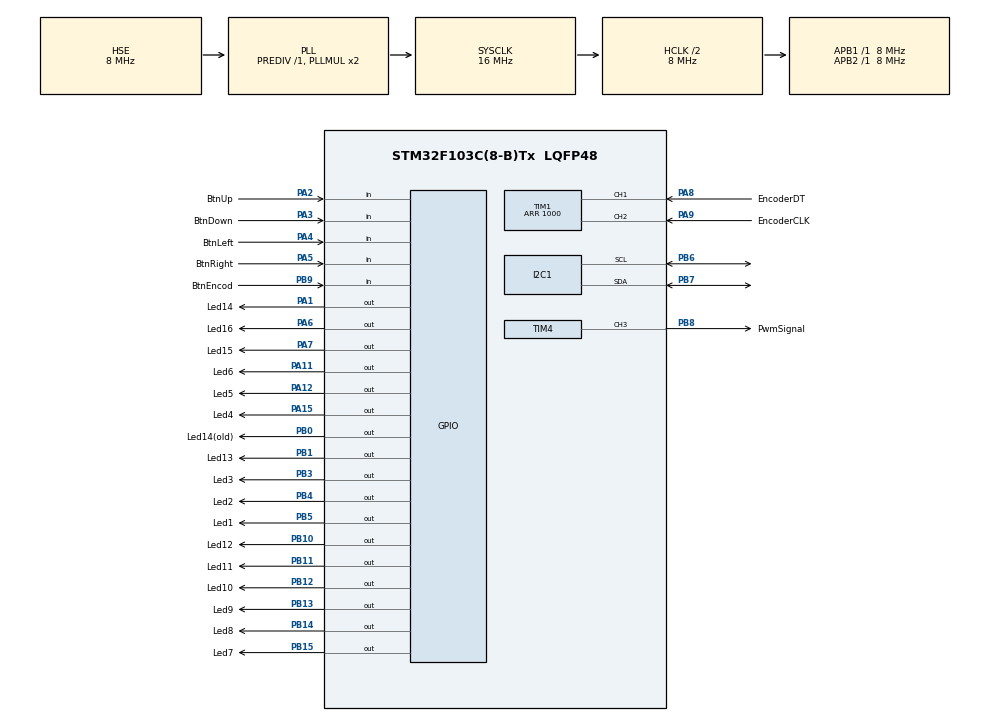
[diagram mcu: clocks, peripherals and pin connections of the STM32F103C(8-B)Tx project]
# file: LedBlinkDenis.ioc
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FREERTOS.BinarySemaphores01=SemBtnUp,Dynamic,NULL;SemBtnDown,Dynamic,NULL;SemBtnLeft,Dynamic,NULL;SemBtnRight,Dynamic,NULL;SemLcdLine1,Dynamic,NULL;SemLcdLine2,Dynamic,NULL;SemLcdLine3,Dynamic,NULL;SemLcdLine4,Dynamic,NULL;SemLcdRedrawMenu,Dynamic,NULL;SemLcdExitMenu,Dynamic,NULL;SemEncoderUp,Dynamic,NULL;SemEncoderDown,Dynamic,NULL;SemEncodBusy,Dynamic,NULL;SemLedMode1,Dynamic,NULL;SemLedMode2,Dynamic,NULL;SemLedMode3,Dynamic,NULL;SemLedMode4,Dynamic,NULL;SemLedMode5,Dynamic,NULL;SemLedMode6,Dynamic,NULL;SemLedMode7,Dynamic,NULL;SemLedMode8,Dynamic,NULL;SemLedMode9,Dynamic,NULL;SemLedMode10,Dynamic,NULL;SemBtnEncod,Dynamic,NULL
FREERTOS.Tasks01=TskMain_,0,128,TskMain,Default,NULL,Dynamic,NULL,NULL;TskReadBtn_,0,128,TskReadBtn,Default,NULL,Dynamic,NULL,NULL;TskReadEncoder_,0,128,TskReadEncoder,Default,NULL,Dynamic,NULL,NULL;TskLedBlink_,0,128,TskLedBlink,Default,NULL,Dynamic,NULL,NULL
FREERTOS.configTOTAL_HEAP_SIZE=15000
Mcu.Family=STM32F1
Mcu.Name=STM32F103C(8-B)Tx
Mcu.Package=LQFP48
NVIC.PriorityGroup=NVIC_PRIORITYGROUP_4
NVIC.TIM3_IRQn=true\:0\:0\:false\:false\:true\:false\:false
NVIC.TimeBase=TIM3_IRQn
NVIC.TimeBaseIP=TIM3
PA1.GPIO_Label=Led14
PA1.GPIO_PuPd=GPIO_PULLDOWN
PA1.Signal=GPIO_Output
PA11.GPIO_Label=Led6
PA11.GPIO_PuPd=GPIO_PULLDOWN
PA11.Signal=GPIO_Output
PA12.GPIO_Label=Led5
PA12.GPIO_PuPd=GPIO_PULLDOWN
PA12.Signal=GPIO_Output
PA13.Mode=Serial_Wire
PA13.Signal=SYS_JTMS-SWDIO
PA14.Mode=Serial_Wire
PA14.Signal=SYS_JTCK-SWCLK
PA15.GPIO_Label=Led4
PA15.GPIO_PuPd=GPIO_PULLDOWN
PA15.Signal=GPIO_Output
PA2.GPIO_Label=BtnUp
PA2.GPIO_PuPd=GPIO_PULLDOWN
PA2.Signal=GPIO_Input
PA3.GPIO_Label=BtnDown
PA3.GPIO_PuPd=GPIO_PULLDOWN
PA3.Signal=GPIO_Input
PA4.GPIO_Label=BtnLeft
PA4.GPIO_PuPd=GPIO_PULLDOWN
PA4.Signal=GPIO_Input
PA5.GPIO_Label=BtnRight
PA5.GPIO_PuPd=GPIO_PULLDOWN
PA5.Signal=GPIO_Input
PA6.GPIO_Label=Led16
PA6.GPIO_PuPd=GPIO_PULLDOWN
PA6.Signal=GPIO_Output
PA7.GPIO_Label=Led15
PA7.GPIO_PuPd=GPIO_PULLDOWN
PA7.Signal=GPIO_Output
PA8.GPIO_Label=EncoderDT
PA8.Signal=S_TIM1_CH1
PA9.GPIO_Label=EncoderCLK
PA9.Signal=S_TIM1_CH2
PB0.GPIO_Label=Led14(old)
PB0.GPIO_PuPd=GPIO_PULLDOWN
PB0.Signal=GPIO_Output
PB1.GPIO_Label=Led13
PB1.GPIO_PuPd=GPIO_PULLDOWN
PB1.Signal=GPIO_Output
PB10.GPIO_Label=Led12
PB10.GPIO_PuPd=GPIO_PULLDOWN
PB10.Signal=GPIO_Output
PB11.GPIO_Label=Led11
PB11.GPIO_PuPd=GPIO_PULLDOWN
PB11.Signal=GPIO_Output
PB12.GPIO_Label=Led10
PB12.GPIO_PuPd=GPIO_PULLDOWN
PB12.Signal=GPIO_Output
PB13.GPIO_Label=Led9
PB13.GPIO_PuPd=GPIO_PULLDOWN
PB13.Signal=GPIO_Output
PB14.GPIO_Label=Led8
PB14.GPIO_PuPd=GPIO_PULLDOWN
PB14.Signal=GPIO_Output
PB15.GPIO_Label=Led7
PB15.GPIO_PuPd=GPIO_PULLDOWN
PB15.Signal=GPIO_Output
PB3.GPIO_Label=Led3
PB3.GPIO_PuPd=GPIO_PULLDOWN
PB3.Signal=GPIO_Output
PB4.GPIO_Label=Led2
PB4.GPIO_PuPd=GPIO_PULLDOWN
PB4.Signal=GPIO_Output
PB5.GPIO_Label=Led1
PB5.GPIO_PuPd=GPIO_PULLDOWN
PB5.Signal=GPIO_Output
PB6.Mode=I2C
PB6.Signal=I2C1_SCL
PB7.Mode=I2C
PB7.Signal=I2C1_SDA
PB8.GPIO_Label=PwmSignal
PB8.Signal=S_TIM4_CH3
PB9.GPIO_Label=BtnEncod
PB9.Signal=GPIO_Input
PD0-OSC_IN.Mode=HSE-External-Oscillator
PD0-OSC_IN.Signal=RCC_OSC_IN
PD1-OSC_OUT.Mode=HSE-External-Oscillator
PD1-OSC_OUT.Signal=RCC_OSC_OUT
ProjectManager.HeapSize=0x200
ProjectManager.StackSize=0x400
ProjectManager.TargetToolchain=MDK-ARM V5
RCC.AHBCLKDivider=RCC_SYSCLK_DIV2
RCC.AHBFreq_Value=8000000
RCC.APB1Freq_Value=8000000
RCC.APB1TimFreq_Value=8000000
RCC.APB2Freq_Value=8000000
RCC.APB2TimFreq_Value=8000000
RCC.HCLKFreq_Value=8000000
RCC.PLLSourceVirtual=RCC_PLLSOURCE_HSE
RCC.SYSCLKFreq_VALUE=16000000
RCC.SYSCLKSource=RCC_SYSCLKSOURCE_PLLCLK
RCC.USBFreq_Value=16000000
SH.S_TIM1_CH1.0=TIM1_CH1,Encoder_Interface
SH.S_TIM1_CH2.0=TIM1_CH2,Encoder_Interface
SH.S_TIM4_CH3.0=TIM4_CH3,PWM Generation3 CH3
TIM1.EncoderMode=TIM_ENCODERMODE_TI12
TIM1.IC1Filter=15
TIM1.IC2Filter=15
TIM1.IC2Polarity=TIM_ICPOLARITY_FALLING
TIM1.Period=1000
TIM4.Channel-PWM\ Generation3\ CH3=TIM_CHANNEL_3
TIM4.Period=55000
VP_FREERTOS_VS_ENABLE.Mode=Enabled
VP_SYS_VS_tim3.Mode=TIM3
board=custom

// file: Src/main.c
/**
  ******************************************************************************
  * @file           : main.c
  * @brief          : Main program body
  ******************************************************************************
  * This notice applies to any and all portions of this file
  * that are not between comment pairs USER CODE BEGIN and
  * USER CODE END. Other portions of this file, whether
  * inserted by the user or by software development tools
  * are owned by their respective copyright owners.
  *
  * Copyright (c) 2020 STMicroelectronics International N.V.
  * All rights reserved.
  *
  * Redistribution and use in source and binary forms, with or without
  * modification, are permitted, provided that the following conditions are met:
  *
  * 1. Redistribution of source code must retain the above copyright notice,
  *    this list of conditions and the following disclaimer.
  * 2. Redistributions in binary form must reproduce the above copyright notice,
  *    this list of conditions and the following disclaimer in the documentation
  *    and/or other materials provided with the distribution.
  * 3. Neither the name of STMicroelectronics nor the names of other
  *    contributors to this software may be used to endorse or promote products
  *    derived from this software without specific written permission.
  * 4. This software, including modifications and/or derivative works of this
  *    software, must execute solely and exclusively on microcontroller or
  *    microprocessor devices manufactured by or for STMicroelectronics.
  * 5. Redistribution and use of this software other than as permitted under
  *    this license is void and will automatically terminate your rights under
  *    this license.
  *
  * THIS SOFTWARE IS PROVIDED BY STMICROELECTRONICS AND CONTRIBUTORS "AS IS"
  * AND ANY EXPRESS, IMPLIED OR STATUTORY WARRANTIES, INCLUDING, BUT NOT
  * LIMITED TO, THE IMPLIED WARRANTIES OF MERCHANTABILITY, FITNESS FOR A
  * PARTICULAR PURPOSE AND NON-INFRINGEMENT OF THIRD PARTY INTELLECTUAL PROPERTY
  * RIGHTS ARE DISCLAIMED TO THE FULLEST EXTENT PERMITTED BY LAW. IN NO EVENT
  * SHALL STMICROELECTRONICS OR CONTRIBUTORS BE LIABLE FOR ANY DIRECT, INDIRECT,
  * INCIDENTAL, SPECIAL, EXEMPLARY, OR CONSEQUENTIAL DAMAGES (INCLUDING, BUT NOT
  * LIMITED TO, PROCUREMENT OF SUBSTITUTE GOODS OR SERVICES; LOSS OF USE, DATA,
  * OR PROFITS; OR BUSINESS INTERRUPTION) HOWEVER CAUSED AND ON ANY THEORY OF
  * LIABILITY, WHETHER IN CONTRACT, STRICT LIABILITY, OR TORT (INCLUDING
  * NEGLIGENCE OR OTHERWISE) ARISING IN ANY WAY OUT OF THE USE OF THIS SOFTWARE,
  * EVEN IF ADVISED OF THE POSSIBILITY OF SUCH DAMAGE.
  *
  ******************************************************************************
  */
#include "main.h"
#include "stm32f1xx_hal.h"
#include "cmsis_os.h"
#include "i2c.h"
#include "tim.h"
#include "gpio.h"

/* USER CODE BEGIN PV */
/* Private variables ---------------------------------------------------------*/

/* USER CODE END PV */

void SystemClock_Config(void);
void MX_FREERTOS_Init(void);

/* USER CODE BEGIN PFP */
/* Private function prototypes -----------------------------------------------*/

/* USER CODE END PFP */

int main(void)
{

  /* MCU Configuration----------------------------------------------------------*/

  /* Reset of all peripherals, Initializes the Flash interface and the Systick. */
  HAL_Init();

  /* Configure the system clock */
  SystemClock_Config();

  /* Initialize all configured peripherals */
  MX_GPIO_Init();
  MX_I2C1_Init();
  MX_TIM1_Init();
  MX_TIM4_Init();

  /* Call init function for freertos objects (in freertos.c) */
  MX_FREERTOS_Init();

  /* Start scheduler */
  osKernelStart();

  /* We should never get here as control is now taken by the scheduler */

  /* Infinite loop */
  while (1)
  {

  }

}

void SystemClock_Config(void)
{

  RCC_OscInitTypeDef RCC_OscInitStruct;
  RCC_ClkInitTypeDef RCC_ClkInitStruct;

    /**Initializes the CPU, AHB and APB busses clocks
    */
  RCC_OscInitStruct.OscillatorType = RCC_OSCILLATORTYPE_HSE;
  RCC_OscInitStruct.HSEState = RCC_HSE_ON;
  RCC_OscInitStruct.HSEPredivValue = RCC_HSE_PREDIV_DIV1;
  RCC_OscInitStruct.HSIState = RCC_HSI_ON;
  RCC_OscInitStruct.PLL.PLLState = RCC_PLL_ON;
  RCC_OscInitStruct.PLL.PLLSource = RCC_PLLSOURCE_HSE;
  RCC_OscInitStruct.PLL.PLLMUL = RCC_PLL_MUL2;
  if (HAL_RCC_OscConfig(&RCC_OscInitStruct) != HAL_OK)
  {
    _Error_Handler(__FILE__, __LINE__);
  }

    /**Initializes the CPU, AHB and APB busses clocks
    */
  RCC_ClkInitStruct.ClockType = RCC_CLOCKTYPE_HCLK|RCC_CLOCKTYPE_SYSCLK
                              |RCC_CLOCKTYPE_PCLK1|RCC_CLOCKTYPE_PCLK2;
  RCC_ClkInitStruct.SYSCLKSource = RCC_SYSCLKSOURCE_PLLCLK;
  RCC_ClkInitStruct.AHBCLKDivider = RCC_SYSCLK_DIV2;
  RCC_ClkInitStruct.APB1CLKDivider = RCC_HCLK_DIV1;
  RCC_ClkInitStruct.APB2CLKDivider = RCC_HCLK_DIV1;

  if (HAL_RCC_ClockConfig(&RCC_ClkInitStruct, FLASH_LATENCY_0) != HAL_OK)
  {
    _Error_Handler(__FILE__, __LINE__);
  }

    /**Configure the Systick interrupt time
    */
  HAL_SYSTICK_Config(HAL_RCC_GetHCLKFreq()/1000);

    /**Configure the Systick
    */
  HAL_SYSTICK_CLKSourceConfig(SYSTICK_CLKSOURCE_HCLK);

  /* SysTick_IRQn interrupt configuration */
  HAL_NVIC_SetPriority(SysTick_IRQn, 15, 0);
}

void HAL_TIM_PeriodElapsedCallback(TIM_HandleTypeDef *htim)
{
  if (htim->Instance == TIM3) {
    HAL_IncTick();
  }
}

void _Error_Handler(char *file, int line)
{
  while(1)
  {
  }
}

/************************ (C) COPYRIGHT STMicroelectronics *****END OF FILE****/

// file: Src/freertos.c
/**
  ******************************************************************************
  * File Name          : freertos.c
  * Description        : Code for freertos applications
  ******************************************************************************
  * This notice applies to any and all portions of this file
  * that are not between comment pairs USER CODE BEGIN and
  * USER CODE END. Other portions of this file, whether
  * inserted by the user or by software development tools
  * are owned by their respective copyright owners.
  *
  * Copyright (c) 2020 STMicroelectronics International N.V.
  * All rights reserved.
  *
  * Redistribution and use in source and binary forms, with or without
  * modification, are permitted, provided that the following conditions are met:
  *
  * 1. Redistribution of source code must retain the above copyright notice,
  *    this list of conditions and the following disclaimer.
  * 2. Redistributions in binary form must reproduce the above copyright notice,
  *    this list of conditions and the following disclaimer in the documentation
  *    and/or other materials provided with the distribution.
  * 3. Neither the name of STMicroelectronics nor the names of other
  *    contributors to this software may be used to endorse or promote products
  *    derived from this software without specific written permission.
  * 4. This software, including modifications and/or derivative works of this
  *    software, must execute solely and exclusively on microcontroller or
  *    microprocessor devices manufactured by or for STMicroelectronics.
  * 5. Redistribution and use of this software other than as permitted under
  *    this license is void and will automatically terminate your rights under
  *    this license.
  *
  * THIS SOFTWARE IS PROVIDED BY STMICROELECTRONICS AND CONTRIBUTORS "AS IS"
  * AND ANY EXPRESS, IMPLIED OR STATUTORY WARRANTIES, INCLUDING, BUT NOT
  * LIMITED TO, THE IMPLIED WARRANTIES OF MERCHANTABILITY, FITNESS FOR A
  * PARTICULAR PURPOSE AND NON-INFRINGEMENT OF THIRD PARTY INTELLECTUAL PROPERTY
  * RIGHTS ARE DISCLAIMED TO THE FULLEST EXTENT PERMITTED BY LAW. IN NO EVENT
  * SHALL STMICROELECTRONICS OR CONTRIBUTORS BE LIABLE FOR ANY DIRECT, INDIRECT,
  * INCIDENTAL, SPECIAL, EXEMPLARY, OR CONSEQUENTIAL DAMAGES (INCLUDING, BUT NOT
  * LIMITED TO, PROCUREMENT OF SUBSTITUTE GOODS OR SERVICES; LOSS OF USE, DATA,
  * OR PROFITS; OR BUSINESS INTERRUPTION) HOWEVER CAUSED AND ON ANY THEORY OF
  * LIABILITY, WHETHER IN CONTRACT, STRICT LIABILITY, OR TORT (INCLUDING
  * NEGLIGENCE OR OTHERWISE) ARISING IN ANY WAY OUT OF THE USE OF THIS SOFTWARE,
  * EVEN IF ADVISED OF THE POSSIBILITY OF SUCH DAMAGE.
  *
  ******************************************************************************
  */

#include "FreeRTOS.h"
#include "task.h"
#include "cmsis_os.h"

/* USER CODE BEGIN Includes */
#include "tsk_main.h"
#include "tsk_btns.h"
#include "tsk_encoder.h"
#include "tsk_led.h"
/* USER CODE END Includes */

osThreadId TskMain_Handle;
osThreadId TskReadBtn_Handle;
osThreadId TskReadEncoder_Handle;
osThreadId TskLedBlink_Handle;
osSemaphoreId SemBtnUpHandle;
osSemaphoreId SemBtnDownHandle;
osSemaphoreId SemBtnLeftHandle;
osSemaphoreId SemBtnRightHandle;
osSemaphoreId SemLcdLine1Handle;
osSemaphoreId SemLcdLine2Handle;
osSemaphoreId SemLcdLine3Handle;
osSemaphoreId SemLcdLine4Handle;
osSemaphoreId SemLcdRedrawMenuHandle;
osSemaphoreId SemLcdExitMenuHandle;
osSemaphoreId SemEncoderUpHandle;
osSemaphoreId SemEncoderDownHandle;
osSemaphoreId SemEncodBusyHandle;
osSemaphoreId SemLedMode1Handle;
osSemaphoreId SemLedMode2Handle;
osSemaphoreId SemLedMode3Handle;
osSemaphoreId SemLedMode4Handle;
osSemaphoreId SemLedMode5Handle;
osSemaphoreId SemLedMode6Handle;
osSemaphoreId SemLedMode7Handle;
osSemaphoreId SemLedMode8Handle;
osSemaphoreId SemLedMode9Handle;
osSemaphoreId SemLedMode10Handle;
osSemaphoreId SemBtnEncodHandle;

void TskMain(void const * argument);
void TskReadBtn(void const * argument);
void TskReadEncoder(void const * argument);
void TskLedBlink(void const * argument);

void MX_FREERTOS_Init(void); /* (MISRA C 2004 rule 8.1) */

/* Hook prototypes */

/* Init FreeRTOS */

void MX_FREERTOS_Init(void) {

  /* Create the semaphores(s) */
  /* definition and creation of SemBtnUp */
  osSemaphoreDef(SemBtnUp);
  SemBtnUpHandle = osSemaphoreCreate(osSemaphore(SemBtnUp), 1);

  /* definition and creation of SemBtnDown */
  osSemaphoreDef(SemBtnDown);
  SemBtnDownHandle = osSemaphoreCreate(osSemaphore(SemBtnDown), 1);

  /* definition and creation of SemBtnLeft */
  osSemaphoreDef(SemBtnLeft);
  SemBtnLeftHandle = osSemaphoreCreate(osSemaphore(SemBtnLeft), 1);

  /* definition and creation of SemBtnRight */
  osSemaphoreDef(SemBtnRight);
  SemBtnRightHandle = osSemaphoreCreate(osSemaphore(SemBtnRight), 1);

  /* definition and creation of SemLcdLine1 */
  osSemaphoreDef(SemLcdLine1);
  SemLcdLine1Handle = osSemaphoreCreate(osSemaphore(SemLcdLine1), 1);

  /* definition and creation of SemLcdLine2 */
  osSemaphoreDef(SemLcdLine2);
  SemLcdLine2Handle = osSemaphoreCreate(osSemaphore(SemLcdLine2), 1);

  /* definition and creation of SemLcdLine3 */
  osSemaphoreDef(SemLcdLine3);
  SemLcdLine3Handle = osSemaphoreCreate(osSemaphore(SemLcdLine3), 1);

  /* definition and creation of SemLcdLine4 */
  osSemaphoreDef(SemLcdLine4);
  SemLcdLine4Handle = osSemaphoreCreate(osSemaphore(SemLcdLine4), 1);

  /* definition and creation of SemLcdRedrawMenu */
  osSemaphoreDef(SemLcdRedrawMenu);
  SemLcdRedrawMenuHandle = osSemaphoreCreate(osSemaphore(SemLcdRedrawMenu), 1);

  /* definition and creation of SemLcdExitMenu */
  osSemaphoreDef(SemLcdExitMenu);
  SemLcdExitMenuHandle = osSemaphoreCreate(osSemaphore(SemLcdExitMenu), 1);

  /* definition and creation of SemEncoderUp */
  osSemaphoreDef(SemEncoderUp);
  SemEncoderUpHandle = osSemaphoreCreate(osSemaphore(SemEncoderUp), 1);

  /* definition and creation of SemEncoderDown */
  osSemaphoreDef(SemEncoderDown);
  SemEncoderDownHandle = osSemaphoreCreate(osSemaphore(SemEncoderDown), 1);

  /* definition and creation of SemEncodBusy */
  osSemaphoreDef(SemEncodBusy);
  SemEncodBusyHandle = osSemaphoreCreate(osSemaphore(SemEncodBusy), 1);

  /* definition and creation of SemLedMode1 */
  osSemaphoreDef(SemLedMode1);
  SemLedMode1Handle = osSemaphoreCreate(osSemaphore(SemLedMode1), 1);

  /* definition and creation of SemLedMode2 */
  osSemaphoreDef(SemLedMode2);
  SemLedMode2Handle = osSemaphoreCreate(osSemaphore(SemLedMode2), 1);

  /* definition and creation of SemLedMode3 */
  osSemaphoreDef(SemLedMode3);
  SemLedMode3Handle = osSemaphoreCreate(osSemaphore(SemLedMode3), 1);

  /* definition and creation of SemLedMode4 */
  osSemaphoreDef(SemLedMode4);
  SemLedMode4Handle = osSemaphoreCreate(osSemaphore(SemLedMode4), 1);

  /* definition and creation of SemLedMode5 */
  osSemaphoreDef(SemLedMode5);
  SemLedMode5Handle = osSemaphoreCreate(osSemaphore(SemLedMode5), 1);

  /* definition and creation of SemLedMode6 */
  osSemaphoreDef(SemLedMode6);
  SemLedMode6Handle = osSemaphoreCreate(osSemaphore(SemLedMode6), 1);

  /* definition and creation of SemLedMode7 */
  osSemaphoreDef(SemLedMode7);
  SemLedMode7Handle = osSemaphoreCreate(osSemaphore(SemLedMode7), 1);

  /* definition and creation of SemLedMode8 */
  osSemaphoreDef(SemLedMode8);
  SemLedMode8Handle = osSemaphoreCreate(osSemaphore(SemLedMode8), 1);

  /* definition and creation of SemLedMode9 */
  osSemaphoreDef(SemLedMode9);
  SemLedMode9Handle = osSemaphoreCreate(osSemaphore(SemLedMode9), 1);

  /* definition and creation of SemLedMode10 */
  osSemaphoreDef(SemLedMode10);
  SemLedMode10Handle = osSemaphoreCreate(osSemaphore(SemLedMode10), 1);

  /* definition and creation of SemBtnEncod */
  osSemaphoreDef(SemBtnEncod);
  SemBtnEncodHandle = osSemaphoreCreate(osSemaphore(SemBtnEncod), 1);

  /* Create the thread(s) */
  /* definition and creation of TskMain_ */
  osThreadDef(TskMain_, TskMain, osPriorityNormal, 0, 128);
  TskMain_Handle = osThreadCreate(osThread(TskMain_), NULL);

  /* definition and creation of TskReadBtn_ */
  osThreadDef(TskReadBtn_, TskReadBtn, osPriorityNormal, 0, 128);
  TskReadBtn_Handle = osThreadCreate(osThread(TskReadBtn_), NULL);

  /* definition and creation of TskReadEncoder_ */
  osThreadDef(TskReadEncoder_, TskReadEncoder, osPriorityNormal, 0, 128);
  TskReadEncoder_Handle = osThreadCreate(osThread(TskReadEncoder_), NULL);

  /* definition and creation of TskLedBlink_ */
  osThreadDef(TskLedBlink_, TskLedBlink, osPriorityNormal, 0, 128);
  TskLedBlink_Handle = osThreadCreate(osThread(TskLedBlink_), NULL);

}

/* TskMain function */
void TskMain(void const * argument)
{

  /* USER CODE BEGIN TskMain */
	/* Infinite loop */
	for(;;)
	{
		tsk_main();
	}
  /* USER CODE END TskMain */
}

/* TskReadBtn function */
void TskReadBtn(void const * argument)
{
  /* USER CODE BEGIN TskReadBtn */
	/* Infinite loop */
	for(;;)
	{
		readBtns();
	}
  /* USER CODE END TskReadBtn */
}

/* TskReadEncoder function */
void TskReadEncoder(void const * argument)
{
  /* USER CODE BEGIN TskReadEncoder */
	/* Infinite loop */
	for(;;)
	{
		tsk_encoder();
	}
  /* USER CODE END TskReadEncoder */
}

/* TskLedBlink function */
void TskLedBlink(void const * argument)
{
  /* USER CODE BEGIN TskLedBlink */
	/* Infinite loop */
	for(;;)
	{
		tsk_led();
	}
  /* USER CODE END TskLedBlink */
}

/************************ (C) COPYRIGHT STMicroelectronics *****END OF FILE****/
